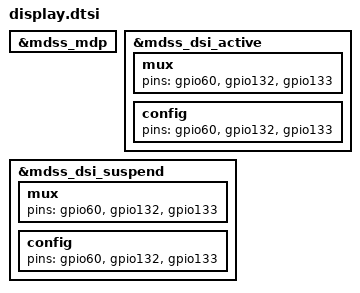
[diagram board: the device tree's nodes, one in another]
/* From stock msm8937-mdss-panels.dtsi */
#include "panel/dsi-panel-ili9881c-hdplus-video.dtsi"
#include "panel/dsi-panel-ili9881c-hdplus-video_c3e.dtsi"
#include "panel/dsi-panel-ili9881d-hdplus-video_c3e.dtsi"
#include "panel/dsi-panel-jd9365z-hdplus-video_c3e.dtsi"
#include "panel/dsi-panel-ili9881h-hdplus-video_c3i.dtsi"
#include "panel/dsi-panel-nvt36525b-hdplus-video_c3i.dtsi"
#include "panel/dsi-panel-ft8006s-hdplus-video_c3i.dtsi"

&mdss_mdp {
	/delete-node/ qcom,mdss_dsi_edo_rm67162_qvga_cmd;
};

/* From stock sdm439-qrd.dtsi */
&mdss_dsi_active {
	mux {
		pins = "gpio60","gpio132","gpio133";
	};
	config {
		pins = "gpio60","gpio132","gpio133";
	};
};
&mdss_dsi_suspend {
	mux {
		pins = "gpio60","gpio132","gpio133";
	};
	config {
		pins = "gpio60","gpio132","gpio133";
	};
};
